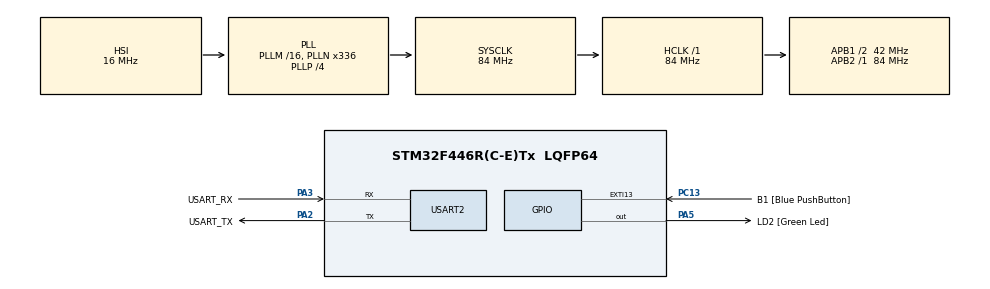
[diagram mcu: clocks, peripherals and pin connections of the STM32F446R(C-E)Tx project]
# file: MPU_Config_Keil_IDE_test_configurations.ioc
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Mcu.Family=STM32F4
Mcu.Name=STM32F446R(C-E)Tx
Mcu.Package=LQFP64
NVIC.PriorityGroup=NVIC_PRIORITYGROUP_0
PA13.GPIO_Label=TMS
PA13.Mode=Serial_Wire
PA13.Signal=SYS_JTMS-SWDIO
PA14.GPIO_Label=TCK
PA14.Mode=Serial_Wire
PA14.Signal=SYS_JTCK-SWCLK
PA2.GPIO_Label=USART_TX
PA2.Mode=Asynchronous
PA2.Signal=USART2_TX
PA3.GPIO_Label=USART_RX
PA3.Mode=Asynchronous
PA3.Signal=USART2_RX
PA5.GPIO_Label=LD2 [Green Led]
PA5.Signal=GPIO_Output
PB3.GPIO_Label=SWO
PB3.Signal=SYS_JTDO-SWO
PC13.GPIO_Label=B1 [Blue PushButton]
PC13.GPIO_ModeDefaultEXTI=GPIO_MODE_IT_FALLING
PC13.Signal=GPXTI13
PC14-OSC32_IN.Mode=LSE-External-Oscillator
PC14-OSC32_IN.Signal=RCC_OSC32_IN
PC15-OSC32_OUT.Mode=LSE-External-Oscillator
PC15-OSC32_OUT.Signal=RCC_OSC32_OUT
PH0-OSC_IN.Mode=HSE-External-Oscillator
PH0-OSC_IN.Signal=RCC_OSC_IN
PH1-OSC_OUT.Mode=HSE-External-Oscillator
PH1-OSC_OUT.Signal=RCC_OSC_OUT
ProjectManager.HeapSize=0x200
ProjectManager.StackSize=0x400
ProjectManager.TargetToolchain=MDK-ARM V5
RCC.48MHZClocksFreq_Value=84000000
RCC.AHBFreq_Value=84000000
RCC.APB1CLKDivider=RCC_HCLK_DIV2
RCC.APB1Freq_Value=42000000
RCC.APB1TimFreq_Value=84000000
RCC.APB2Freq_Value=84000000
RCC.APB2TimFreq_Value=84000000
RCC.CortexFreq_Value=84000000
RCC.FLatency-AdvancedSettings=FLASH_LATENCY_2
RCC.HCLKFreq_Value=84000000
RCC.HSE_VALUE=8000000
RCC.HSI_VALUE=16000000
RCC.PLLN=336
RCC.PLLP=RCC_PLLP_DIV4
RCC.SYSCLKFreq_VALUE=84000000
RCC.SYSCLKSource=RCC_SYSCLKSOURCE_PLLCLK
RCC.USBFreq_Value=168000000
RCC.VCOOutputFreq_Value=336000000
USART2.VirtualMode=VM_ASYNC
board=NUCLEO-F446RE

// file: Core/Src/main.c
/* USER CODE BEGIN Header */
/**
  ******************************************************************************
  * @file           : main.c
  * @brief          : Main program body with MPU configuration and test fault
  ******************************************************************************
  * @attention
  *
  * Copyright (c) 2025 STMicroelectronics.
  * All rights reserved.
  *
  * This software is licensed under terms that can be found in the LICENSE file
  * in the root directory of this software component.
  * If no LICENSE file comes with this software, it is provided AS-IS.
  *
  ******************************************************************************
  */
/* USER CODE END Header */

#include "main.h"
#include "stm32f4xx.h"  // Adjust for your MCU

UART_HandleTypeDef huart2;

void SystemClock_Config(void);
static void MX_GPIO_Init(void);
static void MX_USART2_UART_Init(void);
/* USER CODE BEGIN PFP */
void MPU_Config(void);
void Test_MPU_Fault(void);
/* USER CODE END PFP */

int main(void)
{

  /* MCU Configuration--------------------------------------------------------*/

  /* Reset of all peripherals, Initializes the Flash interface and the Systick. */
  HAL_Init();

  /* Configure the system clock */
  SystemClock_Config();

  /* Initialize all configured peripherals */
  MX_GPIO_Init();
  MX_USART2_UART_Init();

  /* USER CODE BEGIN 2 */
  // Configure the MPU: region 0 for SRAM (or as needed) and region 1 as forbidden
  MPU_Config();
  /* USER CODE END 2 */

  /* Test the MPU configuration by attempting to write to a forbidden region */
  Test_MPU_Fault();

  /* Infinite loop */
  while (1)
  {
    /* USER CODE BEGIN WHILE */
    /* Main application code can go here */
    /* USER CODE END WHILE */

  }
}

/**
  * @brief Configure the MPU attributes.
  * This function disables the MPU, configures region 0 for SRAM and region 1
  * as a forbidden memory area (No Access), then re-enables the MPU.
  * @retval None
  */
void MPU_Config(void)
{
    // Disable the MPU
    MPU->CTRL = 0;

    /* Region 0: Assume SRAM region (for example, 32KB at 0x20000000)
       You may adjust settings as needed. */
  // Region 0: SRAM region (32KB) with full read/write access
MPU->RNR = 0;                // Select region 0
MPU->RBAR = 0x20000000;        // Base address for SRAM
MPU->RASR =
    (0b000 << MPU_RASR_AP_Pos) |        // Full access: Privileged and Unprivileged R/W
    (0b001 << MPU_RASR_TEX_Pos) |       // TEX: Normal memory
    (0 << MPU_RASR_C_Pos) |             // Not cacheable
    (0 << MPU_RASR_B_Pos) |             // Not bufferable
    (14 << MPU_RASR_SIZE_Pos) |         // 32KB region (2^(14+1))
    (1 << MPU_RASR_ENABLE_Pos);         // Enable region

// Region 1: 256-byte block starting at 0x20008000 with full read/write access
MPU->RNR = 1;                // Select region 1
MPU->RBAR = 0x20008000;        // Base address for region 1
MPU->RASR =
    (0b011 << MPU_RASR_AP_Pos) |        // Full access: Privileged and Unprivileged R/W
    (0 << MPU_RASR_TEX_Pos) |           // TEX: Not used here
    (0 << MPU_RASR_C_Pos) |             // Not cacheable
    (0 << MPU_RASR_B_Pos) |             // Not bufferable
    (7 << MPU_RASR_SIZE_Pos) |          // 256 bytes region (2^(7+1)=256)
    (1 << MPU_RASR_ENABLE_Pos);         // Enable region

    // Enable MemManage fault handler
    SCB->SHCSR |= SCB_SHCSR_MEMFAULTENA_Msk;

    // Enable MPU with default memory map for privileged access
    MPU->CTRL = MPU_CTRL_PRIVDEFENA_Msk | MPU_CTRL_ENABLE_Msk;

    // Memory barriers to ensure MPU configuration takes effect immediately
    __DSB();
    __ISB();
}

/**
  * @brief Test the MPU configuration.
  * This function deliberately writes to the forbidden memory region to trigger a
  * MemManage fault.
  * @retval None
  */
void Test_MPU_Fault(void)
{
    volatile uint32_t *forbidden_addr = (uint32_t *)0x20000000;
    // The following write should trigger a MemManage fault
    *forbidden_addr = 0xDEADBEEF;
}

void SystemClock_Config(void)
{
  RCC_OscInitTypeDef RCC_OscInitStruct = {0};
  RCC_ClkInitTypeDef RCC_ClkInitStruct = {0};

  __HAL_RCC_PWR_CLK_ENABLE();
  __HAL_PWR_VOLTAGESCALING_CONFIG(PWR_REGULATOR_VOLTAGE_SCALE3);

  RCC_OscInitStruct.OscillatorType = RCC_OSCILLATORTYPE_HSI;
  RCC_OscInitStruct.HSIState = RCC_HSI_ON;
  RCC_OscInitStruct.HSICalibrationValue = RCC_HSICALIBRATION_DEFAULT;
  RCC_OscInitStruct.PLL.PLLState = RCC_PLL_ON;
  RCC_OscInitStruct.PLL.PLLSource = RCC_PLLSOURCE_HSI;
  RCC_OscInitStruct.PLL.PLLM = 16;
  RCC_OscInitStruct.PLL.PLLN = 336;
  RCC_OscInitStruct.PLL.PLLP = RCC_PLLP_DIV4;
  RCC_OscInitStruct.PLL.PLLQ = 2;
  RCC_OscInitStruct.PLL.PLLR = 2;
  if (HAL_RCC_OscConfig(&RCC_OscInitStruct) != HAL_OK)
  {
    Error_Handler();
  }

  RCC_ClkInitStruct.ClockType = RCC_CLOCKTYPE_HCLK|RCC_CLOCKTYPE_SYSCLK
                              |RCC_CLOCKTYPE_PCLK1|RCC_CLOCKTYPE_PCLK2;
  RCC_ClkInitStruct.SYSCLKSource = RCC_SYSCLKSOURCE_PLLCLK;
  RCC_ClkInitStruct.AHBCLKDivider = RCC_SYSCLK_DIV1;
  RCC_ClkInitStruct.APB1CLKDivider = RCC_HCLK_DIV2;
  RCC_ClkInitStruct.APB2CLKDivider = RCC_HCLK_DIV1;

  if (HAL_RCC_ClockConfig(&RCC_ClkInitStruct, FLASH_LATENCY_2) != HAL_OK)
  {
    Error_Handler();
  }
}

static void MX_USART2_UART_Init(void)
{
  huart2.Instance = USART2;
  huart2.Init.BaudRate = 115200;
  huart2.Init.WordLength = UART_WORDLENGTH_8B;
  huart2.Init.StopBits = UART_STOPBITS_1;
  huart2.Init.Parity = UART_PARITY_NONE;
  huart2.Init.Mode = UART_MODE_TX_RX;
  huart2.Init.HwFlowCtl = UART_HWCONTROL_NONE;
  huart2.Init.OverSampling = UART_OVERSAMPLING_16;
  if (HAL_UART_Init(&huart2) != HAL_OK)
  {
    Error_Handler();
  }
}

static void MX_GPIO_Init(void)
{
  GPIO_InitTypeDef GPIO_InitStruct = {0};

  /* GPIO Ports Clock Enable */
  __HAL_RCC_GPIOC_CLK_ENABLE();
  __HAL_RCC_GPIOH_CLK_ENABLE();
  __HAL_RCC_GPIOA_CLK_ENABLE();
  __HAL_RCC_GPIOB_CLK_ENABLE();

  /*Configure GPIO pin Output Level */
  HAL_GPIO_WritePin(LD2_GPIO_Port, LD2_Pin, GPIO_PIN_RESET);

  /*Configure GPIO pin : B1_Pin */
  GPIO_InitStruct.Pin = B1_Pin;
  GPIO_InitStruct.Mode = GPIO_MODE_IT_FALLING;
  GPIO_InitStruct.Pull = GPIO_NOPULL;
  HAL_GPIO_Init(B1_GPIO_Port, &GPIO_InitStruct);

  /*Configure GPIO pin : LD2_Pin */
  GPIO_InitStruct.Pin = LD2_Pin;
  GPIO_InitStruct.Mode = GPIO_MODE_OUTPUT_PP;
  GPIO_InitStruct.Pull = GPIO_NOPULL;
  GPIO_InitStruct.Speed = GPIO_SPEED_FREQ_LOW;
  HAL_GPIO_Init(LD2_GPIO_Port, &GPIO_InitStruct);
}

void Error_Handler(void)
{
  __disable_irq();
  while (1)
  {
  }
}

#ifdef  USE_FULL_ASSERT
void assert_failed(uint8_t *file, uint32_t line)
{
  /* USER CODE BEGIN 6 */
  /* User can add their own implementation to report the file name and line number,
     e.g. printf("Wrong parameters value: file %s on line %d\r\n", file, line) */
  /* USER CODE END 6 */
}
#endif /* USE_FULL_ASSERT */
